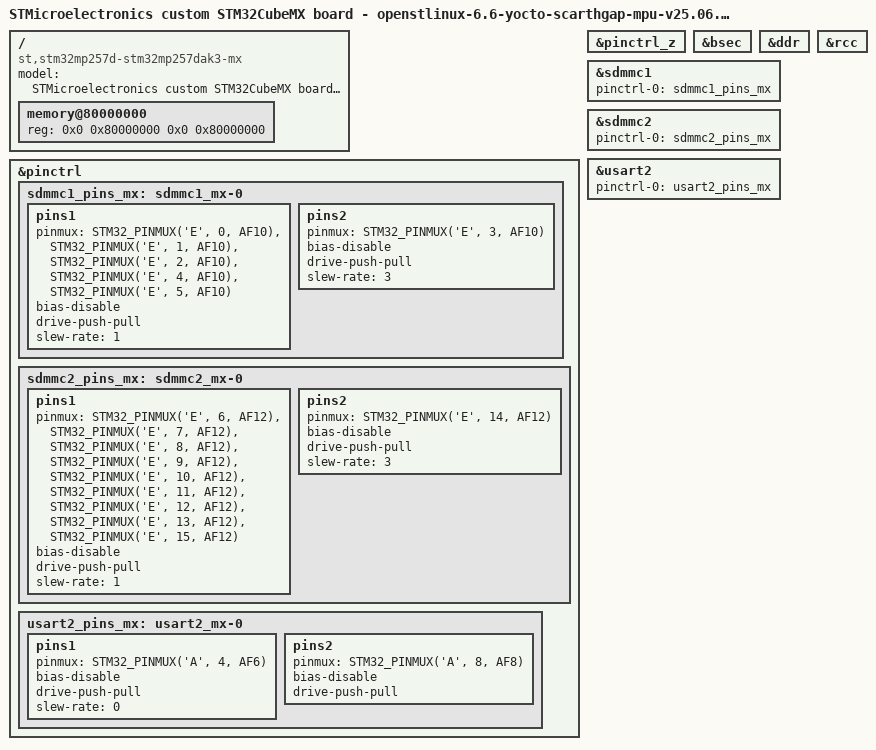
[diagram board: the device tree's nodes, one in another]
// SPDX-License-Identifier: (GPL-2.0-only OR BSD-3-Clause)
/*
 * Copyright (C) 2025, STMicroelectronics - All Rights Reserved
 * Author: STM32CubeMX code generation for STMicroelectronics.
 */

/* For more information on Device Tree configuration, please refer to
 * https://wiki.st.com/stm32mpu/wiki/Category:Device_tree_configuration
 */

/dts-v1/;

#include <dt-bindings/pinctrl/stm32-pinfunc.h>
#include <dt-bindings/clock/stm32mp25-clksrc.h>
#include "stm32mp25-mx.dtsi"

#include "stm32mp257.dtsi"
#include "stm32mp257d-stm32mp257dak3-mx-rcc.dtsi"
#include "stm32mp25xxak-pinctrl.dtsi"
#include "stm32mp25-ddr.dtsi"

/* USER CODE BEGIN includes */
/* USER CODE END includes */

/ {
	model = "STMicroelectronics custom STM32CubeMX board - openstlinux-6.6-yocto-scarthgap-mpu-v25.06.11";
	compatible = "st,stm32mp257d-stm32mp257dak3-mx", "st,stm32mp257";

	memory@80000000 {
		device_type = "memory";
		reg = <0x0 0x80000000 0x0 0x80000000>;

		/* USER CODE BEGIN memory */
		/* USER CODE END memory */
	};

	/* USER CODE BEGIN root */
	/* USER CODE END root */

}; /*root*/

&pinctrl {
	sdmmc1_pins_mx: sdmmc1_mx-0 {
		pins1 {
			pinmux = <STM32_PINMUX('E', 0, AF10)>, /* SDMMC1_D2 */
					 <STM32_PINMUX('E', 1, AF10)>, /* SDMMC1_D3 */
					 <STM32_PINMUX('E', 2, AF10)>, /* SDMMC1_CMD */
					 <STM32_PINMUX('E', 4, AF10)>, /* SDMMC1_D0 */
					 <STM32_PINMUX('E', 5, AF10)>; /* SDMMC1_D1 */
			bias-disable;
			drive-push-pull;
			slew-rate = <1>;
		};
		pins2 {
			pinmux = <STM32_PINMUX('E', 3, AF10)>; /* SDMMC1_CK */
			bias-disable;
			drive-push-pull;
			slew-rate = <3>;
		};
	};

	sdmmc2_pins_mx: sdmmc2_mx-0 {
		pins1 {
			pinmux = <STM32_PINMUX('E', 6, AF12)>, /* SDMMC2_D6 */
					 <STM32_PINMUX('E', 7, AF12)>, /* SDMMC2_D7 */
					 <STM32_PINMUX('E', 8, AF12)>, /* SDMMC2_D2 */
					 <STM32_PINMUX('E', 9, AF12)>, /* SDMMC2_D5 */
					 <STM32_PINMUX('E', 10, AF12)>, /* SDMMC2_D4 */
					 <STM32_PINMUX('E', 11, AF12)>, /* SDMMC2_D1 */
					 <STM32_PINMUX('E', 12, AF12)>, /* SDMMC2_D3 */
					 <STM32_PINMUX('E', 13, AF12)>, /* SDMMC2_D0 */
					 <STM32_PINMUX('E', 15, AF12)>; /* SDMMC2_CMD */
			bias-disable;
			drive-push-pull;
			slew-rate = <1>;
		};
		pins2 {
			pinmux = <STM32_PINMUX('E', 14, AF12)>; /* SDMMC2_CK */
			bias-disable;
			drive-push-pull;
			slew-rate = <3>;
		};
	};

	usart2_pins_mx: usart2_mx-0 {
		pins1 {
			pinmux = <STM32_PINMUX('A', 4, AF6)>; /* USART2_TX */
			bias-disable;
			drive-push-pull;
			slew-rate = <0>;
		};
		pins2 {
			pinmux = <STM32_PINMUX('A', 8, AF8)>; /* USART2_RX */
			bias-disable;
			drive-push-pull;
		};
	};

	/* USER CODE BEGIN pinctrl */
	/* USER CODE END pinctrl */
};

&pinctrl_z {
	/* USER CODE BEGIN pinctrl_z */
	/* USER CODE END pinctrl_z */
};

&bsec {
	status = "okay";

	/* USER CODE BEGIN bsec */
	/* USER CODE END bsec */
};

&ddr {
	status = "okay";

	/* USER CODE BEGIN ddr */
	/* USER CODE END ddr */
};

&rcc {
	status = "okay";

	/* USER CODE BEGIN rcc */
	/* USER CODE END rcc */
};

&sdmmc1 {
	pinctrl-names = "default";
	pinctrl-0 = <&sdmmc1_pins_mx>;
	status = "okay";

	/* USER CODE BEGIN sdmmc1 */
	/* USER CODE END sdmmc1 */
};

&sdmmc2 {
	pinctrl-names = "default";
	pinctrl-0 = <&sdmmc2_pins_mx>;
	status = "okay";

	/* USER CODE BEGIN sdmmc2 */
	/* USER CODE END sdmmc2 */
};

&usart2 {
	pinctrl-names = "default";
	pinctrl-0 = <&usart2_pins_mx>;
	status = "okay";

	/* USER CODE BEGIN usart2 */
	/* USER CODE END usart2 */
};

/* USER CODE BEGIN addons */
/* USER CODE END addons */

